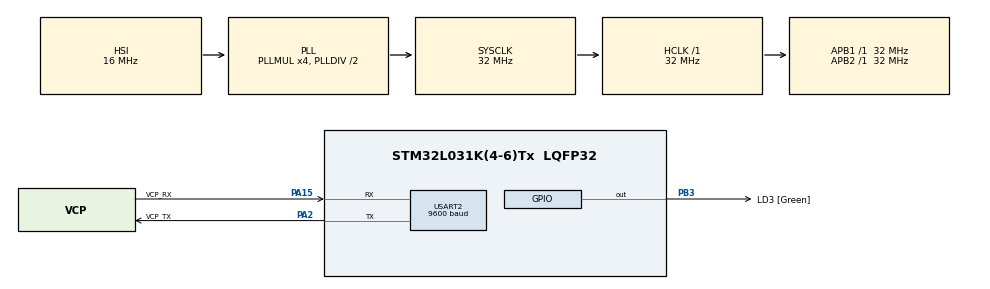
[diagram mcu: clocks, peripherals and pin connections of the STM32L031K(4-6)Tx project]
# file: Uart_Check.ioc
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Mcu.Family=STM32L0
Mcu.Name=STM32L031K(4-6)Tx
Mcu.Package=LQFP32
PA13.GPIO_Label=TMS
PA13.Mode=Serial_Wire
PA13.Signal=SYS_SWDIO
PA14.GPIO_Label=TCK
PA14.Mode=Serial_Wire
PA14.Signal=SYS_SWCLK
PA15.GPIO_Label=VCP_RX
PA15.Mode=Asynchronous
PA15.Signal=USART2_RX
PA2.GPIO_Label=VCP_TX
PA2.Mode=Asynchronous
PA2.Signal=USART2_TX
PB3.GPIO_Label=LD3 [Green]
PB3.Signal=GPIO_Output
PC14-OSC32_IN.Mode=LSE-External-Oscillator
PC14-OSC32_IN.Signal=RCC_OSC32_IN
PC15-OSC32_OUT.Mode=LSE-External-Oscillator
PC15-OSC32_OUT.Signal=RCC_OSC32_OUT
ProjectManager.HeapSize=0x200
ProjectManager.StackSize=0x400
ProjectManager.TargetToolchain=STM32CubeIDE
RCC.AHBFreq_Value=32000000
RCC.APB1Freq_Value=32000000
RCC.APB1TimFreq_Value=32000000
RCC.APB2Freq_Value=32000000
RCC.APB2TimFreq_Value=32000000
RCC.HCLKFreq_Value=32000000
RCC.HSE_VALUE=8000000
RCC.HSI16_VALUE=16000000
RCC.HSI48_VALUE=48000000
RCC.HSI_VALUE=16000000
RCC.MSI_VALUE=2097000
RCC.PLLMUL=RCC_PLLMUL_4
RCC.SYSCLKFreq_VALUE=32000000
RCC.SYSCLKSource=RCC_SYSCLKSOURCE_PLLCLK
RCC.VCOOutputFreq_Value=64000000
USART2.BaudRate=9600
USART2.VirtualMode-Asynchronous=VM_ASYNC
board=NUCLEO-L031K6

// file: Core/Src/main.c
/* USER CODE BEGIN Header */
/**
  ******************************************************************************
  * @file           : main.c
  * @brief          : Main program body
  ******************************************************************************
  * @attention
  *
  * Copyright (c) 2025 STMicroelectronics.
  * All rights reserved.
  *
  * This software is licensed under terms that can be found in the LICENSE file
  * in the root directory of this software component.
  * If no LICENSE file comes with this software, it is provided AS-IS.
  *
  ******************************************************************************
  */
/* USER CODE END Header */
#include "main.h"

/* USER CODE BEGIN Includes */
#include <stdio.h>
#include <string.h>
/* USER CODE END Includes */

/* USER CODE BEGIN PD */
// Function to compute SL30 checksum (sum ASCII values & keep lower 8 bits)
uint8_t compute_checksum(char *data, int length) {
    uint8_t checksum = 0;
    for (int i = 0; i < length; i++) {
        checksum += data[i];  // Sum ASCII values
    }
    return checksum & 0xFF;   // Keep lower 8 bits
}

#define UART_BUFFER_SIZE 8  // Expecting 6 bytes
#define CHECKSUM_LENGTH 3   // Length of the data part "101"
uint8_t uart_rx_buffer[UART_BUFFER_SIZE];  // Buffer to store received data

/* USER CODE END PD */

UART_HandleTypeDef huart2;

void SystemClock_Config(void);
static void MX_GPIO_Init(void);
static void MX_USART2_UART_Init(void);

int main(void)
{

  /* MCU Configuration--------------------------------------------------------*/

  /* Reset of all peripherals, Initializes the Flash interface and the Systick. */
  HAL_Init();

  /* Configure the system clock */
  SystemClock_Config();

  /* Initialize all configured peripherals */
  MX_GPIO_Init();
  MX_USART2_UART_Init();
  /* USER CODE BEGIN 2 */
  int mhz = 256;
  int khz = 475;
  int vol = 45;
  char o = '1';
  char s = '0';
  char T = '0';
  char D = '1';

  // Convert integers to strings
     char mhz_str[4], khz_str[4], vol_str[3];
     sprintf(mhz_str, "%d", mhz);
     sprintf(khz_str, "%d", khz);
     sprintf(vol_str, "%d", vol);

     // Concatenate everything into a buffer
     char data[20];  // Ensure buffer is large enough
     sprintf(data, "%s%s%s%c%c%c%c", mhz_str, khz_str, vol_str, o, s, T, D);

     // Compute checksum
     uint8_t checksum = compute_checksum(data, strlen(data));

     // Store checksum as two uppercase HEX characters
     char checksum_hex[3];
     sprintf(checksum_hex, "%02X", checksum);  // Convert to 2-digit HEX

  char str[20];  // Ensure buffer is large enough

  // Correct sprintf usage
  sprintf(str, "$%d%d%d%c%c%c%c%s\r\n", mhz, khz, vol, o, s, T, D,checksum_hex);

  /* USER CODE END 2 */

  /* Infinite loop */
  /* USER CODE BEGIN WHILE */
  while (1)
  {
//	   HAL_UART_Transmit(&huart2, str, 17, 1000); // to transmit data
	    if (HAL_UART_Receive(&huart2, uart_rx_buffer, UART_BUFFER_SIZE, 2000) == HAL_OK) {
//	        // Data received successfully
	    	char data_rx[CHECKSUM_LENGTH + 1];  // Buffer to store extracted data (3 chars)
	    	    strncpy(data_rx, (char*)&uart_rx_buffer[1], CHECKSUM_LENGTH);
	    	    data_rx[CHECKSUM_LENGTH] = '\0';  // Null-terminate the string

	    	    // Extract checksum part "CC" from the received buffer
	    	    char checksum_str[3];
	    	    snprintf(checksum_str, 3, "%c%c", uart_rx_buffer[4], uart_rx_buffer[5]);

	    	    // Convert checksum "CC" from hex to integer
//	    	    uint8_t received_checksum;
//	    	    sscanf(checksum_str, "%2hhx", &received_checksum);
	    	    uint8_t received_checksum = (uint8_t)strtol(checksum_str, NULL, 16);
	    	    // Calculate checksum of data "101"
	    	    uint8_t calculated_checksum = compute_checksum(data, CHECKSUM_LENGTH);
	        // Process the received data (e.g., print or echo back)
	        HAL_UART_Transmit(&huart2, uart_rx_buffer, UART_BUFFER_SIZE, 2000);  // Echo back received data
	    }
//	   HAL_UART_Transmit(&huart2, str, 17, 1000);
	   HAL_Delay(100);
    /* USER CODE END WHILE */

  }
}

void SystemClock_Config(void)
{
  RCC_OscInitTypeDef RCC_OscInitStruct = {0};
  RCC_ClkInitTypeDef RCC_ClkInitStruct = {0};
  RCC_PeriphCLKInitTypeDef PeriphClkInit = {0};

  /** Configure the main internal regulator output voltage
  */
  __HAL_PWR_VOLTAGESCALING_CONFIG(PWR_REGULATOR_VOLTAGE_SCALE1);

  /** Initializes the RCC Oscillators according to the specified parameters
  * in the RCC_OscInitTypeDef structure.
  */
  RCC_OscInitStruct.OscillatorType = RCC_OSCILLATORTYPE_HSI;
  RCC_OscInitStruct.HSIState = RCC_HSI_ON;
  RCC_OscInitStruct.HSICalibrationValue = RCC_HSICALIBRATION_DEFAULT;
  RCC_OscInitStruct.PLL.PLLState = RCC_PLL_ON;
  RCC_OscInitStruct.PLL.PLLSource = RCC_PLLSOURCE_HSI;
  RCC_OscInitStruct.PLL.PLLMUL = RCC_PLLMUL_4;
  RCC_OscInitStruct.PLL.PLLDIV = RCC_PLLDIV_2;
  if (HAL_RCC_OscConfig(&RCC_OscInitStruct) != HAL_OK)
  {
    Error_Handler();
  }

  /** Initializes the CPU, AHB and APB buses clocks
  */
  RCC_ClkInitStruct.ClockType = RCC_CLOCKTYPE_HCLK|RCC_CLOCKTYPE_SYSCLK
                              |RCC_CLOCKTYPE_PCLK1|RCC_CLOCKTYPE_PCLK2;
  RCC_ClkInitStruct.SYSCLKSource = RCC_SYSCLKSOURCE_PLLCLK;
  RCC_ClkInitStruct.AHBCLKDivider = RCC_SYSCLK_DIV1;
  RCC_ClkInitStruct.APB1CLKDivider = RCC_HCLK_DIV1;
  RCC_ClkInitStruct.APB2CLKDivider = RCC_HCLK_DIV1;

  if (HAL_RCC_ClockConfig(&RCC_ClkInitStruct, FLASH_LATENCY_1) != HAL_OK)
  {
    Error_Handler();
  }
  PeriphClkInit.PeriphClockSelection = RCC_PERIPHCLK_USART2;
  PeriphClkInit.Usart2ClockSelection = RCC_USART2CLKSOURCE_PCLK1;
  if (HAL_RCCEx_PeriphCLKConfig(&PeriphClkInit) != HAL_OK)
  {
    Error_Handler();
  }
}

static void MX_USART2_UART_Init(void)
{

  huart2.Instance = USART2;
  huart2.Init.BaudRate = 115200;
  huart2.Init.WordLength = UART_WORDLENGTH_8B;
  huart2.Init.StopBits = UART_STOPBITS_1;
  huart2.Init.Parity = UART_PARITY_NONE;
  huart2.Init.Mode = UART_MODE_TX_RX;
  huart2.Init.HwFlowCtl = UART_HWCONTROL_NONE;
  huart2.Init.OverSampling = UART_OVERSAMPLING_16;
  huart2.Init.OneBitSampling = UART_ONE_BIT_SAMPLE_DISABLE;
  huart2.AdvancedInit.AdvFeatureInit = UART_ADVFEATURE_NO_INIT;
  if (HAL_UART_Init(&huart2) != HAL_OK)
  {
    Error_Handler();
  }

}

static void MX_GPIO_Init(void)
{
  GPIO_InitTypeDef GPIO_InitStruct = {0};

  /* GPIO Ports Clock Enable */
  __HAL_RCC_GPIOC_CLK_ENABLE();
  __HAL_RCC_GPIOA_CLK_ENABLE();
  __HAL_RCC_GPIOB_CLK_ENABLE();

  /*Configure GPIO pin Output Level */
  HAL_GPIO_WritePin(LD3_GPIO_Port, LD3_Pin, GPIO_PIN_RESET);

  /*Configure GPIO pin : LD3_Pin */
  GPIO_InitStruct.Pin = LD3_Pin;
  GPIO_InitStruct.Mode = GPIO_MODE_OUTPUT_PP;
  GPIO_InitStruct.Pull = GPIO_NOPULL;
  GPIO_InitStruct.Speed = GPIO_SPEED_FREQ_LOW;
  HAL_GPIO_Init(LD3_GPIO_Port, &GPIO_InitStruct);

}

void Error_Handler(void)
{
  __disable_irq();
  while (1)
  {
  }
}
